VERSION ""

NS_ :

BS_:

BU_: ASC
VAL_TABLE_ Vt_B_MSR 1 "MSR regulated " 0 "passive or ASC" ;
VAL_TABLE_ Vt_B_ASC 1 "ASC regulated" 0 "passive or MSR" ;
VAL_TABLE_ Vt_ASC_PAS 1 "ASC passive" 0 "ASC active" ;
VAL_TABLE_ Vt_ASC_REG 1 "intervention active" 0 "no intervention" ;
VAL_TABLE_ Vt_STAT_OIL_PR_LIGHT 1 "on" 0 "off" ;
VAL_TABLE_ Vt_STAT_CHECK_GAS_CAP_LIGHT 1 "on" 0 "off" ;
VAL_TABLE_ Vt_STAT_EML_LIGHT 1 "on" 0 "off" ;
VAL_TABLE_ Vt_STAT_CC_LIGHT 1 "on" 0 "off" ;
VAL_TABLE_ Vt_STAT_CHECK_ENG_LIGHT 1 "on" 0 "off" ;
VAL_TABLE_ Vt_STAT_RPM_WARN_FIELD 7 "4000" 6 "4500" 5 "5000" 4 "5500" 3 "6000" 2 "6500" 1 "7000" 0 "7500" ;
VAL_TABLE_ Vt_S_KUP 1 "Kupplung betätigt" 0 "Kupplung Ruhestellung" ;
VAL_TABLE_ Vt_Q_ASC 1 "ASC-Botschaft i.O." 0 "Fehler in ASC-Botschaft" ;
VAL_TABLE_ Vt_S_KL15 1 "Kl.15 ein" 0 "aus, Selbsthaltephase" ;
VAL_TABLE_ Vt_S_MDASC 1 "ASC-Schnittstelle mit ALIVE-Signal" 0 "ASC-Schnittstelle ohne ALIVE-Signal" ;
VAL_TABLE_ Vt_S_KATH2 1 "Kat-Heizung Bank 2 ein" 0 "Kat-Heizung Bank 2 aus" ;
VAL_TABLE_ Vt_S_KATH1 1 "Kat-Heizung Bank 1 ein" 0 "Kat-Heizung Bank 1 aus" ;
VAL_TABLE_ Vt_S_KD 1 "Kickdown erkannt" 0 "kein Kickdown oder FFP Fehler erkannt" ;
VAL_TABLE_ Vt_F_BS 1 "Fehler erkannt" 0 "fehlerfrei und i.O." ;
VAL_TABLE_ Vt_S_BS 1 "Bremse betätigt" 0 "Bremse Ruhestellung" ;
VAL_TABLE_ Vt_S_NIV_LL 1 "LL-Drehzahl < Schwelle" 0 "LL-Drehzahl > Schwelle" ;
VAL_TABLE_ Vt_BED_FGR 7 "error occured" 6 "not used" 5 "not used" 4 "off" 3 "reset" 2 "set / retard" 1 "set / accelerate" 0 "no operation" ;

BO_ 3221225472 VECTOR__INDEPENDENT_SIG_MSG: 0 Vector__XXX
 SG_ BYTE_6 : 0|8@1+ (1,0) [0|0] "" Vector__XXX
 SG_ BYTE_5 : 0|8@1+ (1,0) [0|0] "" Vector__XXX
 SG_ BYTE_4 : 0|8@1+ (1,0) [0|0] "" Vector__XXX
 SG_ BYTE_3 : 0|8@1+ (1,0) [0|0] "" Vector__XXX
 SG_ BYTE_2 : 0|8@1+ (1,0) [0|0] "" Vector__XXX
 SG_ BYTE_1 : 0|8@1+ (1,0) [0|0] "" Vector__XXX
 SG_ BYTE_0 : 0|8@1+ (1,0) [0|0] "" Vector__XXX
 SG_ STAT_AC : 0|1@1+ (1,0) [0|0] "" Vector__XXX

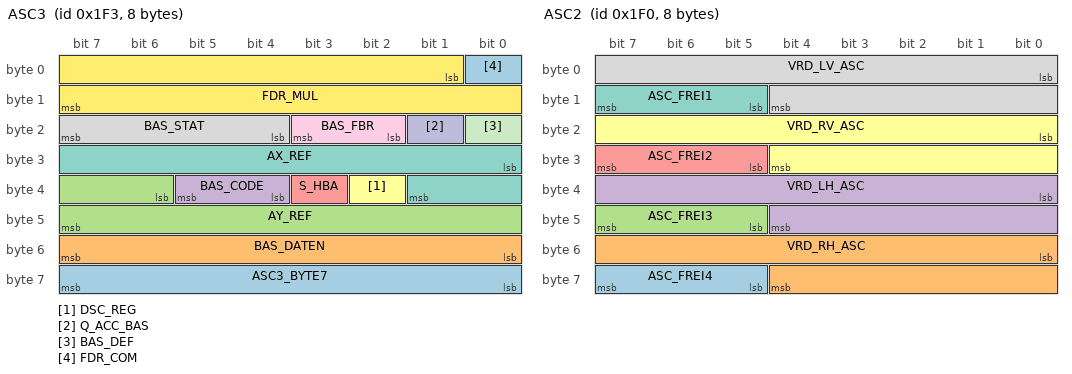
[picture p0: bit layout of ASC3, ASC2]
BO_ 499 ASC3: 8 ASC
 SG_ ASC3_BYTE7 : 56|8@1+ (1,0) [0|0] "" Vector__XXX
 SG_ BAS_DATEN : 48|8@1+ (1,0) [0|0] "" Vector__XXX
 SG_ AY_REF : 38|10@1+ (1,0) [0|0] "" Vector__XXX
 SG_ BAS_CODE : 36|2@1+ (1,0) [0|0] "" Vector__XXX
 SG_ S_HBA : 35|1@1+ (1,0) [0|0] "" Vector__XXX
 SG_ DSC_REG : 34|1@1+ (1,0) [0|0] "" Vector__XXX
 SG_ AX_REF : 24|10@1+ (1,0) [0|0] "" Vector__XXX
 SG_ BAS_STAT : 20|4@1+ (1,0) [0|0] "" Vector__XXX
 SG_ BAS_FBR : 18|2@1+ (1,0) [0|0] "" Vector__XXX
 SG_ Q_ACC_BAS : 17|1@1+ (1,0) [0|0] "" Vector__XXX
 SG_ BAS_DEF : 16|1@1+ (1,0) [0|0] "" Vector__XXX
 SG_ FDR_MUL : 1|15@1+ (1,0) [0|0] "" Vector__XXX
 SG_ FDR_COM : 0|1@1+ (1,0) [0|0] "" Vector__XXX

BO_ 496 ASC2: 8 ASC
 SG_ ASC_FREI4 : 61|3@1- (1,0) [0|0] "" Vector__XXX
 SG_ VRD_RH_ASC : 48|13@1+ (0.0625,0) [0|512] "km/h" Vector__XXX
 SG_ ASC_FREI3 : 45|3@1- (1,0) [0|0] "" Vector__XXX
 SG_ VRD_LH_ASC : 32|13@1+ (0.0625,0) [0|512] "km/h" Vector__XXX
 SG_ ASC_FREI2 : 29|3@1- (1,0) [0|0] "" Vector__XXX
 SG_ VRD_RV_ASC : 16|13@1+ (0.0625,0) [0|512] "km/h" Vector__XXX
 SG_ ASC_FREI1 : 13|3@1- (1,0) [0|0] "" Vector__XXX
 SG_ VRD_LV_ASC : 0|13@1+ (0.0625,0) [0|512] "km/h" Vector__XXX

BO_ 339 ASC1: 8 ASC
 SG_ ASC_ALIVE : 56|4@1+ (1,0) [0|0] "" Vector__XXX
 SG_ MD_IND_ASC_LM : 48|8@1+ (1,0) [0|0] "" Vector__XXX
 SG_ W_VDK : 40|8@1+ (1,0) [0|0] "" Vector__XXX
 SG_ MD_IND_MSR : 32|8@1+ (1,0) [0|0] "" Vector__XXX
 SG_ MD_IND_ASC : 24|8@1+ (1,0) [0|0] "" Vector__XXX
 SG_ V1 : 11|13@1+ (0.0625,0) [0|512] "km/h" Vector__XXX
 SG_ F_V1 : 10|1@1+ (1,0) [0|0] "" Vector__XXX
 SG_ ASC_REG : 9|1@1+ (1,0) [0|0] "" Vector__XXX
 SG_ L_ASC : 8|1@1+ (1,0) [0|0] "" Vector__XXX
 SG_ L_ABS : 7|1@1+ (1,0) [0|0] "" Vector__XXX
 SG_ L_EBV : 6|1@1+ (1,0) [0|0] "" Vector__XXX
 SG_ L_BAS : 5|1@1+ (1,0) [0|0] "" Vector__XXX
 SG_ S_BLS : 4|1@1+ (1,0) [0|0] "" Vector__XXX
 SG_ ASC_SBE : 3|1@1+ (1,0) [0|0] "" Vector__XXX
 SG_ ASC_PAS : 2|1@1+ (1,0) [0|0] "" Vector__XXX
 SG_ B_MSR : 1|1@1+ (1,0) [0|0] "" Vector__XXX
 SG_ B_ASC : 0|1@1+ (1,0) [0|0] "" Vector__XXX

CM_ BO_ 3221225472 "This is a message for not used signals, created by Vector CANdb++ DBC OLE DB Provider.";
CM_ SG_ 3221225472 STAT_AC "Status Klima";
CM_ SG_ 496 VRD_RH_ASC "Geschwindigkeit Rad rechts hinten";
CM_ SG_ 496 VRD_LH_ASC "Geschwindigkeit Rad links hinten";
CM_ SG_ 496 VRD_RV_ASC "Geschwindigkeit Rad rechts vorne";
CM_ SG_ 496 VRD_LV_ASC "Geschwindigkeit Rad links vorne";
CM_ SG_ 339 MD_IND_ASC_LM "optional, oder 0xFF";
CM_ SG_ 339 W_VDK "Optional, oder 0xFF";
CM_ SG_ 339 L_ASC "ASC Lamp";
CM_ SG_ 339 L_ABS "ABS Lamp";
CM_ SG_ 339 ASC_PAS "Status ASC passiv";
CM_ SG_ 339 B_MSR "Demand for MSR";
CM_ SG_ 339 B_ASC "Demand for ASC";
BA_DEF_ SG_  "GenSigStartValue" INT 0 1024;
BA_DEF_ BO_  "GenMsgSendType" ENUM  "Zyklisch ","Ereignisgesteuert ","dummy ","ZyklischImmer";
BA_DEF_ BO_  "GenMsgCycleTime" INT 0 1000000;
BA_DEF_  "BusType" STRING ;
BA_DEF_DEF_  "GenSigStartValue" 0;
BA_DEF_DEF_  "GenMsgSendType" "Zyklisch ";
BA_DEF_DEF_  "GenMsgCycleTime" 0;
BA_DEF_DEF_  "BusType" "CAN";
BA_ "GenMsgCycleTime" BO_ 499 10;
BA_ "GenMsgCycleTime" BO_ 496 10;
BA_ "GenMsgCycleTime" BO_ 339 10;
BA_ "GenSigStartValue" SG_ 339 ASC_PAS 1;
VAL_ 339 ASC_REG 1 "intervention active" 0 "no intervention" ;
VAL_ 339 ASC_PAS 1 "ASC passive" 0 "ASC active" ;
VAL_ 339 B_MSR 1 "MSR regulated " 0 "passive or ASC" ;
VAL_ 339 B_ASC 1 "ASC regulated" 0 "passive or MSR" ;
